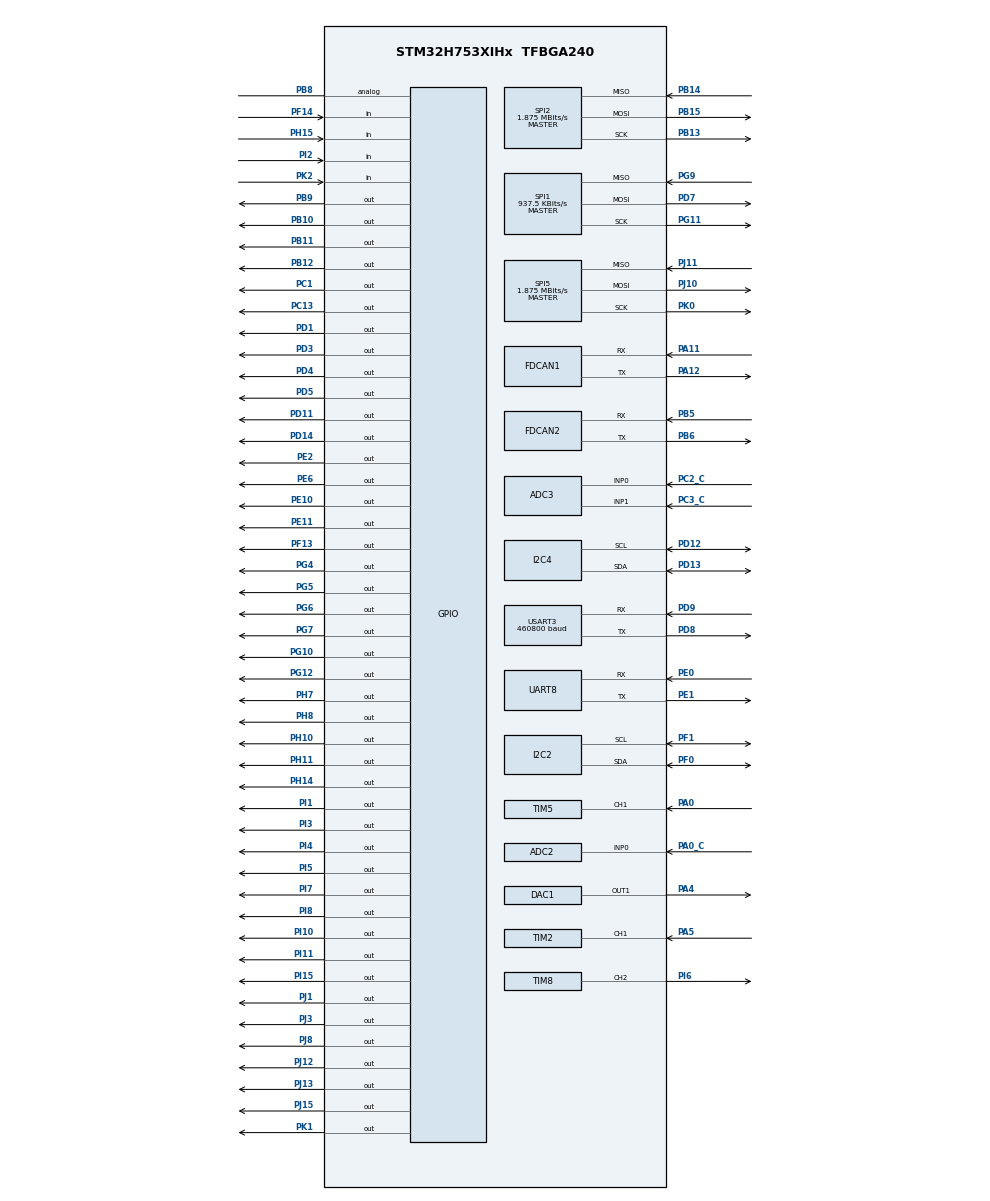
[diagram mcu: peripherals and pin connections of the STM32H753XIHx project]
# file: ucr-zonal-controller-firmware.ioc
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ADC2.Channel-0\#ChannelRegularConversion=ADC_CHANNEL_0
ADC2.ClockPrescaler=ADC_CLOCK_ASYNC_DIV256
ADC2.ContinuousConvMode=ENABLE
ADC2.ConversionDataManagement=ADC_CONVERSIONDATA_DMA_CIRCULAR
ADC2.NbrOfConversionFlag=1
ADC2.OffsetNumber-0\#ChannelRegularConversion=ADC_OFFSET_NONE
ADC2.OffsetSignedSaturation-0\#ChannelRegularConversion=DISABLE
ADC2.Rank-0\#ChannelRegularConversion=1
ADC2.Resolution=ADC_RESOLUTION_12B
ADC2.SamplingTime-0\#ChannelRegularConversion=ADC_SAMPLETIME_810CYCLES_5
ADC3.Channel-2\#ChannelRegularConversion=ADC_CHANNEL_1
ADC3.Channel-3\#ChannelRegularConversion=ADC_CHANNEL_0
ADC3.ClockPrescaler=ADC_CLOCK_ASYNC_DIV256
ADC3.ContinuousConvMode=ENABLE
ADC3.ConversionDataManagement=ADC_CONVERSIONDATA_DMA_CIRCULAR
ADC3.NbrOfConversion=2
ADC3.NbrOfConversionFlag=1
ADC3.OffsetNumber-2\#ChannelRegularConversion=ADC_OFFSET_NONE
ADC3.OffsetNumber-3\#ChannelRegularConversion=ADC_OFFSET_NONE
ADC3.OffsetSignedSaturation-2\#ChannelRegularConversion=DISABLE
ADC3.OffsetSignedSaturation-3\#ChannelRegularConversion=DISABLE
ADC3.Rank-2\#ChannelRegularConversion=1
ADC3.Rank-3\#ChannelRegularConversion=2
ADC3.SamplingTime-2\#ChannelRegularConversion=ADC_SAMPLETIME_810CYCLES_5
ADC3.SamplingTime-3\#ChannelRegularConversion=ADC_SAMPLETIME_810CYCLES_5
CORTEX_M7.default_mode_Activation=1
DAC1.DAC_Channel-DAC_OUT1=DAC_CHANNEL_1
Dma.ADC2.1.Direction=DMA_PERIPH_TO_MEMORY
Dma.ADC2.1.EventEnable=DISABLE
Dma.ADC2.1.FIFOMode=DMA_FIFOMODE_DISABLE
Dma.ADC2.1.Instance=DMA1_Stream1
Dma.ADC2.1.MemDataAlignment=DMA_MDATAALIGN_HALFWORD
Dma.ADC2.1.MemInc=DMA_MINC_ENABLE
Dma.ADC2.1.Mode=DMA_CIRCULAR
Dma.ADC2.1.PeriphDataAlignment=DMA_PDATAALIGN_HALFWORD
Dma.ADC2.1.PeriphInc=DMA_PINC_DISABLE
Dma.ADC2.1.Polarity=HAL_DMAMUX_REQ_GEN_RISING
Dma.ADC2.1.Priority=DMA_PRIORITY_LOW
Dma.ADC2.1.RequestNumber=1
Dma.ADC2.1.SignalID=NONE
Dma.ADC2.1.SyncEnable=DISABLE
Dma.ADC2.1.SyncPolarity=HAL_DMAMUX_SYNC_NO_EVENT
Dma.ADC2.1.SyncRequestNumber=1
Dma.ADC2.1.SyncSignalID=NONE
Dma.ADC3.2.Direction=DMA_PERIPH_TO_MEMORY
Dma.ADC3.2.EventEnable=DISABLE
Dma.ADC3.2.FIFOMode=DMA_FIFOMODE_DISABLE
Dma.ADC3.2.Instance=DMA2_Stream1
Dma.ADC3.2.MemDataAlignment=DMA_MDATAALIGN_HALFWORD
Dma.ADC3.2.MemInc=DMA_MINC_ENABLE
Dma.ADC3.2.Mode=DMA_CIRCULAR
Dma.ADC3.2.PeriphDataAlignment=DMA_PDATAALIGN_HALFWORD
Dma.ADC3.2.PeriphInc=DMA_PINC_DISABLE
Dma.ADC3.2.Polarity=HAL_DMAMUX_REQ_GEN_RISING
Dma.ADC3.2.Priority=DMA_PRIORITY_LOW
Dma.ADC3.2.RequestNumber=1
Dma.ADC3.2.SignalID=NONE
Dma.ADC3.2.SyncEnable=DISABLE
Dma.ADC3.2.SyncPolarity=HAL_DMAMUX_SYNC_NO_EVENT
Dma.ADC3.2.SyncRequestNumber=1
Dma.ADC3.2.SyncSignalID=NONE
Dma.Request0=USART3_RX
Dma.Request1=ADC2
Dma.Request2=ADC3
Dma.USART3_RX.0.Direction=DMA_PERIPH_TO_MEMORY
Dma.USART3_RX.0.EventEnable=DISABLE
Dma.USART3_RX.0.FIFOMode=DMA_FIFOMODE_DISABLE
Dma.USART3_RX.0.Instance=DMA1_Stream0
Dma.USART3_RX.0.MemDataAlignment=DMA_MDATAALIGN_BYTE
Dma.USART3_RX.0.MemInc=DMA_MINC_ENABLE
Dma.USART3_RX.0.Mode=DMA_CIRCULAR
Dma.USART3_RX.0.PeriphDataAlignment=DMA_PDATAALIGN_BYTE
Dma.USART3_RX.0.PeriphInc=DMA_PINC_DISABLE
Dma.USART3_RX.0.Polarity=HAL_DMAMUX_REQ_GEN_RISING
Dma.USART3_RX.0.Priority=DMA_PRIORITY_MEDIUM
Dma.USART3_RX.0.RequestNumber=1
Dma.USART3_RX.0.SignalID=NONE
Dma.USART3_RX.0.SyncEnable=DISABLE
Dma.USART3_RX.0.SyncPolarity=HAL_DMAMUX_SYNC_NO_EVENT
Dma.USART3_RX.0.SyncRequestNumber=1
Dma.USART3_RX.0.SyncSignalID=NONE
FDCAN1.AutoRetransmission=DISABLE
FDCAN1.CalculateBaudRateNominal=499999
FDCAN1.CalculateTimeBitNominal=2000
FDCAN1.CalculateTimeQuantumNominal=250.00000000000003
FDCAN1.DataPrescaler=15
FDCAN1.DataSyncJumpWidth=1
FDCAN1.DataTimeSeg1=2
FDCAN1.DataTimeSeg2=1
FDCAN1.FrameFormat=FDCAN_FRAME_FD_BRS
FDCAN1.Mode=FDCAN_MODE_NORMAL
FDCAN1.NominalPrescaler=30
FDCAN1.NominalSyncJumpWidth=2
FDCAN1.NominalTimeSeg1=5
FDCAN1.NominalTimeSeg2=2
FDCAN1.RxBufferSize=FDCAN_DATA_BYTES_64
FDCAN1.RxFifo0ElmtSize=FDCAN_DATA_BYTES_64
FDCAN1.RxFifo0ElmtsNbr=16
FDCAN1.RxFifo1ElmtSize=FDCAN_DATA_BYTES_64
FDCAN1.RxFifo1ElmtsNbr=16
FDCAN1.StdFiltersNbr=0
FDCAN1.TxElmtSize=FDCAN_DATA_BYTES_64
FDCAN1.TxFifoQueueElmtsNbr=32
FDCAN2.CalculateBaudRateNominal=500000
FDCAN2.CalculateTimeBitNominal=2000
FDCAN2.CalculateTimeQuantumNominal=100.0
FDCAN2.DataPrescaler=12
FDCAN2.DataSyncJumpWidth=8
FDCAN2.DataTimeSeg1=11
FDCAN2.DataTimeSeg2=8
FDCAN2.FrameFormat=FDCAN_FRAME_CLASSIC
FDCAN2.MessageRAMOffset=1280
FDCAN2.Mode=FDCAN_MODE_NORMAL
FDCAN2.NominalPrescaler=12
FDCAN2.NominalSyncJumpWidth=5
FDCAN2.NominalTimeSeg1=14
FDCAN2.NominalTimeSeg2=5
FDCAN2.RxFifo0ElmtSize=FDCAN_DATA_BYTES_8
FDCAN2.RxFifo0ElmtsNbr=16
FDCAN2.RxFifo1ElmtSize=FDCAN_DATA_BYTES_8
FDCAN2.RxFifo1ElmtsNbr=16
FDCAN2.TxElmtSize=FDCAN_DATA_BYTES_8
FDCAN2.TxFifoQueueElmtsNbr=16
FREERTOS.Tasks01=TestTask,41,1024,StartTestTask,Default,NULL,Dynamic,NULL,NULL;SlowTask,8,512,StartSlowTask,Default,NULL,Dynamic,NULL,NULL;MediumTask,16,512,StartMediumTask,Default,NULL,Dynamic,NULL,NULL;FastTask,32,512,StartFastTask,Default,NULL,Dynamic,NULL,NULL;CanClassicTx,24,512,StartCanClassicTx,Default,NULL,Dynamic,NULL,NULL;CanClassicRx,40,512,StartCanClassicRx,Default,NULL,Dynamic,NULL,NULL;ManagerTask,40,512,StartManagerTask,Default,NULL,Dynamic,NULL,NULL;VeryFastTask,16,256,StartVeryFastTask,Default,NULL,Dynamic,NULL,NULL
FREERTOS.configTOTAL_HEAP_SIZE=32768
FREERTOS.configUSE_NEWLIB_REENTRANT=1
I2C2.Timing=0x307075B1
I2C4.Timing=0x307075B1
Mcu.Family=STM32H7
Mcu.Name=STM32H753XIHx
Mcu.Package=TFBGA240
NVIC.ADC3_IRQn=true\:5\:0\:false\:false\:true\:true\:true\:true\:true
NVIC.ADC_IRQn=true\:5\:0\:false\:false\:true\:true\:true\:true\:true
NVIC.DMA1_Stream0_IRQn=true\:5\:0\:false\:false\:true\:true\:false\:true\:true
NVIC.DMA1_Stream1_IRQn=true\:5\:0\:false\:false\:true\:true\:false\:true\:true
NVIC.DMA2_Stream1_IRQn=true\:5\:0\:false\:false\:true\:true\:false\:true\:true
NVIC.FDCAN1_IT0_IRQn=true\:5\:0\:false\:false\:true\:true\:true\:true\:true
NVIC.FDCAN1_IT1_IRQn=true\:5\:0\:false\:false\:true\:true\:true\:true\:true
NVIC.FDCAN2_IT0_IRQn=true\:5\:0\:false\:false\:true\:true\:true\:true\:true
NVIC.FDCAN2_IT1_IRQn=true\:5\:0\:false\:false\:true\:true\:true\:true\:true
NVIC.PriorityGroup=NVIC_PRIORITYGROUP_4
NVIC.SPI1_IRQn=true\:5\:0\:false\:false\:true\:true\:true\:true\:true
NVIC.TIM1_UP_IRQn=true\:15\:0\:false\:false\:true\:false\:false\:true\:true
NVIC.TIM2_IRQn=true\:5\:0\:false\:false\:true\:true\:true\:true\:true
NVIC.TIM5_IRQn=true\:5\:0\:false\:false\:true\:true\:true\:true\:true
NVIC.TimeBase=TIM1_UP_IRQn
NVIC.TimeBaseIP=TIM1
NVIC.USART3_IRQn=true\:5\:0\:false\:false\:true\:true\:true\:true\:true
PA0.Signal=S_TIM5_CH1
PA0_C.Signal=ADCx_INP0
PA11.Mode=FDCAN_Activate
PA11.Signal=FDCAN1_RX
PA12.Mode=FDCAN_Activate
PA12.Signal=FDCAN1_TX
PA13\ (JTMS/SWDIO).Mode=JTAG_4_pins
PA13\ (JTMS/SWDIO).Signal=DEBUG_JTMS-SWDIO
PA14\ (JTCK/SWCLK).Mode=JTAG_4_pins
PA14\ (JTCK/SWCLK).Signal=DEBUG_JTCK-SWCLK
PA15\ (JTDI).Mode=JTAG_4_pins
PA15\ (JTDI).Signal=DEBUG_JTDI
PA4.Signal=COMP_DAC11_group
PA5.Signal=S_TIM2_CH1_ETR
PB10.Signal=GPIO_Output
PB11.Signal=GPIO_Output
PB12.Signal=GPIO_Output
PB13.Mode=Full_Duplex_Master
PB13.Signal=SPI2_SCK
PB14.Mode=Full_Duplex_Master
PB14.Signal=SPI2_MISO
PB15.Mode=Full_Duplex_Master
PB15.Signal=SPI2_MOSI
PB3\ (JTDO/TRACESWO).Mode=JTAG_4_pins
PB3\ (JTDO/TRACESWO).Signal=DEBUG_JTDO-SWO
PB5.Mode=FDCAN_Activate
PB5.Signal=FDCAN2_RX
PB6.Mode=FDCAN_Activate
PB6.Signal=FDCAN2_TX
PB8.Signal=GPIO_Analog
PB9.Signal=GPIO_Output
PC1.Signal=GPIO_Output
PC13.Signal=GPIO_Output
PC14-OSC32_IN\ (OSC32_IN).Mode=LSE-External-Oscillator
PC14-OSC32_IN\ (OSC32_IN).Signal=RCC_OSC32_IN
PC15-OSC32_OUT\ (OSC32_OUT).Mode=LSE-External-Oscillator
PC15-OSC32_OUT\ (OSC32_OUT).Signal=RCC_OSC32_OUT
PC2_C.Mode=IN0-Single-Ended
PC2_C.Signal=ADC3_INP0
PC3_C.Mode=IN1-Single-Ended
PC3_C.Signal=ADC3_INP1
PD1.Signal=GPIO_Output
PD11.Signal=GPIO_Output
PD12.Mode=I2C
PD12.Signal=I2C4_SCL
PD13.Mode=I2C
PD13.Signal=I2C4_SDA
PD14.Signal=GPIO_Output
PD3.Signal=GPIO_Output
PD4.Signal=GPIO_Output
PD5.Signal=GPIO_Output
PD7.Mode=Full_Duplex_Master
PD7.Signal=SPI1_MOSI
PD8.Mode=Asynchronous
PD8.Signal=USART3_TX
PD9.Mode=Asynchronous
PD9.Signal=USART3_RX
PE0.Mode=Asynchronous
PE0.Signal=UART8_RX
PE1.Mode=Asynchronous
PE1.Signal=UART8_TX
PE10.Signal=GPIO_Output
PE11.Signal=GPIO_Output
PE2.Signal=GPIO_Output
PE6.Signal=GPIO_Output
PF0.Mode=I2C
PF0.Signal=I2C2_SDA
PF1.Mode=I2C
PF1.Signal=I2C2_SCL
PF13.PinState=GPIO_PIN_SET
PF13.Signal=GPIO_Output
PF14.GPIO_PuPd=GPIO_PULLUP
PF14.Signal=GPIO_Input
PG10.Signal=GPIO_Output
PG11.Mode=Full_Duplex_Master
PG11.Signal=SPI1_SCK
PG12.Signal=GPIO_Output
PG4.Signal=GPIO_Output
PG5.Signal=GPIO_Output
PG6.Signal=GPIO_Output
PG7.Signal=GPIO_Output
PG9.Mode=Full_Duplex_Master
PG9.Signal=SPI1_MISO
PH0-OSC_IN\ (PH0).Mode=HSE-External-Oscillator
PH0-OSC_IN\ (PH0).Signal=RCC_OSC_IN
PH1-OSC_OUT\ (PH1).Mode=HSE-External-Oscillator
PH1-OSC_OUT\ (PH1).Signal=RCC_OSC_OUT
PH10.Signal=GPIO_Output
PH11.Signal=GPIO_Output
PH14.Signal=GPIO_Output
PH15.Signal=GPIO_Input
PH7.Signal=GPIO_Output
PH8.Signal=GPIO_Output
PI1.Signal=GPIO_Output
PI10.Signal=GPIO_Output
PI11.Signal=GPIO_Output
PI15.Signal=GPIO_Output
PI2.Signal=GPIO_Input
PI3.Signal=GPIO_Output
PI4.Signal=GPIO_Output
PI5.Signal=GPIO_Output
PI6.Signal=S_TIM8_CH2
PI7.Signal=GPIO_Output
PI8.Signal=GPIO_Output
PJ1.Signal=GPIO_Output
PJ10.Mode=Full_Duplex_Master
PJ10.Signal=SPI5_MOSI
PJ11.Mode=Full_Duplex_Master
PJ11.Signal=SPI5_MISO
PJ12.Signal=GPIO_Output
PJ13.PinState=GPIO_PIN_SET
PJ13.Signal=GPIO_Output
PJ15.Signal=GPIO_Output
PJ3.PinState=GPIO_PIN_SET
PJ3.Signal=GPIO_Output
PJ8.Signal=GPIO_Output
PK0.Mode=Full_Duplex_Master
PK0.Signal=SPI5_SCK
PK1.Signal=GPIO_Output
PK2.Signal=GPIO_Input
ProjectManager.HeapSize=0x200
ProjectManager.StackSize=0x400
ProjectManager.TargetToolchain=STM32CubeIDE
RCC.ADCFreq_Value=80000000
RCC.APB1Freq_Value=120000000
RCC.APB2Freq_Value=120000000
RCC.APB3Freq_Value=120000000
RCC.APB4Freq_Value=120000000
RCC.CortexFreq_Value=480000000
RCC.D1PPRE=RCC_APB3_DIV2
RCC.D2PPRE1=RCC_APB1_DIV2
RCC.D2PPRE2=RCC_APB2_DIV2
RCC.D3PPRE=RCC_APB4_DIV2
RCC.DIVM1=5
RCC.DIVM2=5
RCC.DIVN1=192
RCC.DIVN2=32
RCC.DIVQ1=8
RCC.HCLKFreq_Value=240000000
RCC.HPRE=RCC_HCLK_DIV2
RCC.HSE_Timout=500
RCC.HSE_VALUE=25000000
RCC.PLL2FRACN=0
RCC.PLL3FRACN=0
RCC.PLLFRACN=0
RCC.PLLSourceVirtual=RCC_PLLSOURCE_HSE
RCC.RTCClockSelection=RCC_RTCCLKSOURCE_LSE
RCC.SYSCLKFreq_VALUE=480000000
RCC.SYSCLKSource=RCC_SYSCLKSOURCE_PLLCLK
RCC.USBFreq_Value=120000000
SH.ADCx_INP0.0=ADC2_INP0,IN0-Single-Ended
SH.COMP_DAC11_group.0=DAC1_OUT1,DAC_OUT1
SH.S_TIM2_CH1_ETR.0=TIM2_CH1,Input_Capture1_from_TI1
SH.S_TIM5_CH1.0=TIM5_CH1,Input_Capture1_from_TI1
SH.S_TIM8_CH2.0=TIM8_CH2,PWM Generation2 CH2
SPI1.BaudRatePrescaler=SPI_BAUDRATEPRESCALER_128
SPI1.CLKPhase=SPI_PHASE_2EDGE
SPI1.CalculateBaudRate=937.5 KBits/s
SPI1.DataSize=SPI_DATASIZE_8BIT
SPI1.Direction=SPI_DIRECTION_2LINES
SPI1.Mode=SPI_MODE_MASTER
SPI1.VirtualType=VM_MASTER
SPI2.BaudRatePrescaler=SPI_BAUDRATEPRESCALER_64
SPI2.CalculateBaudRate=1.875 MBits/s
SPI2.DataSize=SPI_DATASIZE_8BIT
SPI2.Direction=SPI_DIRECTION_2LINES
SPI2.Mode=SPI_MODE_MASTER
SPI2.VirtualType=VM_MASTER
SPI5.BaudRatePrescaler=SPI_BAUDRATEPRESCALER_64
SPI5.CLKPhase=SPI_PHASE_1EDGE
SPI5.CalculateBaudRate=1.875 MBits/s
SPI5.DataSize=SPI_DATASIZE_8BIT
SPI5.Direction=SPI_DIRECTION_2LINES
SPI5.Mode=SPI_MODE_MASTER
SPI5.VirtualType=VM_MASTER
TIM2.Channel-Input_Capture1_from_TI1=TIM_CHANNEL_1
TIM2.Period=4294967295
TIM2.Prescaler=239
TIM5.Channel-Input_Capture1_from_TI1=TIM_CHANNEL_1
TIM5.Prescaler=239
TIM8.AutoReloadPreload=TIM_AUTORELOAD_PRELOAD_ENABLE
TIM8.Channel-PWM\ Generation2\ CH2=TIM_CHANNEL_2
TIM8.Prescaler=35
USART3.BaudRate=460800
USART3.VirtualMode-Asynchronous=VM_ASYNC
VP_FREERTOS_VS_CMSIS_V2.Mode=CMSIS_V2
VP_MEMORYMAP_VS_MEMORYMAP.Mode=CurAppReg
VP_RTC_VS_RTC_Activate.Mode=RTC_Enabled
VP_SYS_VS_tim1.Mode=TIM1
VP_TIM2_VS_ClockSourceINT.Mode=Internal
VP_TIM3_VS_ClockSourceINT.Mode=Internal
VP_TIM5_VS_ClockSourceINT.Mode=Internal
VP_VREFBUF_V_VREFBUF.Mode=ExternalMode
board=custom

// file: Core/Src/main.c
/* USER CODE BEGIN Header */
/**
  ******************************************************************************
  * @file           : main.c
  * @brief          : Main program body
  ******************************************************************************
  * @attention
  *
  * Copyright (c) 2026 STMicroelectronics.
  * All rights reserved.
  *
  * This software is licensed under terms that can be found in the LICENSE file
  * in the root directory of this software component.
  * If no LICENSE file comes with this software, it is provided AS-IS.
  *
  ******************************************************************************
  */
/* USER CODE END Header */
#include "main.h"
#include "cmsis_os.h"

/* USER CODE BEGIN Includes */

#include "task_test.h"
#include "task_fast.h"
#include "task_very_fast.h"
#include "task_medium.h"
#include "task_slow.h"
#include "task_can_classic_tx.h"
#include "task_can_classic_rx.h"
#include "task_manager.h"

/* USER CODE END Includes */

ADC_HandleTypeDef hadc2;
ADC_HandleTypeDef hadc3;
DMA_HandleTypeDef hdma_adc2;
DMA_HandleTypeDef hdma_adc3;

DAC_HandleTypeDef hdac1;

FDCAN_HandleTypeDef hfdcan1;
FDCAN_HandleTypeDef hfdcan2;

I2C_HandleTypeDef hi2c2;
I2C_HandleTypeDef hi2c4;

RTC_HandleTypeDef hrtc;

SPI_HandleTypeDef hspi1;
SPI_HandleTypeDef hspi2;
SPI_HandleTypeDef hspi5;

TIM_HandleTypeDef htim2;
TIM_HandleTypeDef htim3;
TIM_HandleTypeDef htim5;
TIM_HandleTypeDef htim8;

UART_HandleTypeDef huart8;
UART_HandleTypeDef huart3;
DMA_HandleTypeDef hdma_usart3_rx;

/* Definitions for TestTask */
osThreadId_t TestTaskHandle;
const osThreadAttr_t TestTask_attributes = {
  .name = "TestTask",
  .stack_size = 1024 * 4,
  .priority = (osPriority_t) osPriorityHigh1,
};
/* Definitions for SlowTask */
osThreadId_t SlowTaskHandle;
const osThreadAttr_t SlowTask_attributes = {
  .name = "SlowTask",
  .stack_size = 512 * 4,
  .priority = (osPriority_t) osPriorityLow,
};
/* Definitions for MediumTask */
osThreadId_t MediumTaskHandle;
const osThreadAttr_t MediumTask_attributes = {
  .name = "MediumTask",
  .stack_size = 512 * 4,
  .priority = (osPriority_t) osPriorityBelowNormal,
};
/* Definitions for FastTask */
osThreadId_t FastTaskHandle;
const osThreadAttr_t FastTask_attributes = {
  .name = "FastTask",
  .stack_size = 512 * 4,
  .priority = (osPriority_t) osPriorityAboveNormal,
};
/* Definitions for CanClassicTx */
osThreadId_t CanClassicTxHandle;
const osThreadAttr_t CanClassicTx_attributes = {
  .name = "CanClassicTx",
  .stack_size = 512 * 4,
  .priority = (osPriority_t) osPriorityNormal,
};
/* Definitions for CanClassicRx */
osThreadId_t CanClassicRxHandle;
const osThreadAttr_t CanClassicRx_attributes = {
  .name = "CanClassicRx",
  .stack_size = 512 * 4,
  .priority = (osPriority_t) osPriorityHigh,
};
/* Definitions for ManagerTask */
osThreadId_t ManagerTaskHandle;
const osThreadAttr_t ManagerTask_attributes = {
  .name = "ManagerTask",
  .stack_size = 512 * 4,
  .priority = (osPriority_t) osPriorityHigh,
};
/* Definitions for VeryFastTask */
osThreadId_t VeryFastTaskHandle;
const osThreadAttr_t VeryFastTask_attributes = {
  .name = "VeryFastTask",
  .stack_size = 256 * 4,
  .priority = (osPriority_t) osPriorityBelowNormal,
};
/* USER CODE BEGIN PV */
/* Definitions for Can1TxQueue */

uint32_t captureValue = 0;
uint32_t previousCaptureValue = 0;
uint32_t frequency = 0;

osMessageQueueId_t Can1TxQueueHandle;
const osMessageQueueAttr_t Can1TxQueue_attributes = {
  .name = "Can1TxQueue"
};

osMessageQueueId_t Can1RxQueueHandle;
const osMessageQueueAttr_t Can1RxQueue_attributes = {
  .name = "Can1RxQueue"
};

osMessageQueueId_t Can2TxQueueHandle;
const osMessageQueueAttr_t Can2TxQueue_attributes = {
  .name = "Can2TxQueue"
};

osMessageQueueId_t Can2RxQueueHandle;
const osMessageQueueAttr_t Can2RxQueue_attributes = {
  .name = "Can2RxQueue"
};
/* USER CODE END PV */

void SystemClock_Config(void);
void PeriphCommonClock_Config(void);
static void MPU_Config(void);
static void MX_GPIO_Init(void);
static void MX_DMA_Init(void);
static void MX_ADC3_Init(void);
static void MX_DAC1_Init(void);
static void MX_FDCAN1_Init(void);
static void MX_FDCAN2_Init(void);
static void MX_I2C2_Init(void);
static void MX_I2C4_Init(void);
static void MX_SPI1_Init(void);
static void MX_SPI2_Init(void);
static void MX_SPI5_Init(void);
static void MX_UART8_Init(void);
static void MX_USART3_UART_Init(void);
static void MX_TIM3_Init(void);
static void MX_TIM2_Init(void);
static void MX_RTC_Init(void);
static void MX_ADC2_Init(void);
static void MX_TIM8_Init(void);
static void MX_TIM5_Init(void);
void StartTestTask(void *argument);
void StartSlowTask(void *argument);
void StartMediumTask(void *argument);
void StartFastTask(void *argument);
void StartCanClassicTx(void *argument);
void StartCanClassicRx(void *argument);
void StartManagerTask(void *argument);
void StartVeryFastTask(void *argument);

/* USER CODE BEGIN 0 */

//void HAL_TIM_IC_CaptureCallback(TIM_HandleTypeDef *htim)
//{
//    if (htim->Channel == HAL_TIM_ACTIVE_CHANNEL_1) {
//        captureValue = HAL_TIM_ReadCapturedValue(htim, TIM_CHANNEL_1);
//        frequency = HAL_RCC_GetPCLK1Freq() / (captureValue - previousCaptureValue);
//        previousCaptureValue = captureValue;
//    }
//}

/* USER CODE END 0 */

int main(void)
{

  /* MPU Configuration--------------------------------------------------------*/
  MPU_Config();

  /* MCU Configuration--------------------------------------------------------*/

  /* Reset of all peripherals, Initializes the Flash interface and the Systick. */
  HAL_Init();

  /* Configure the system clock */
  SystemClock_Config();

  /* Configure the peripherals common clocks */
  PeriphCommonClock_Config();

  /* Initialize all configured peripherals */
  MX_GPIO_Init();
  MX_DMA_Init();
  MX_ADC3_Init();
  MX_DAC1_Init();
  MX_FDCAN1_Init();
  MX_FDCAN2_Init();
  MX_I2C2_Init();
  MX_I2C4_Init();
  MX_SPI1_Init();
  MX_SPI2_Init();
  MX_SPI5_Init();
  MX_UART8_Init();
  MX_USART3_UART_Init();
  MX_TIM3_Init();
  MX_TIM2_Init();
  MX_RTC_Init();
  MX_ADC2_Init();
  MX_TIM8_Init();
  MX_TIM5_Init();

  /* Init scheduler */
  osKernelInitialize();

  /* USER CODE BEGIN RTOS_QUEUES */
  Can1TxQueueHandle = osMessageQueueNew (16, sizeof(can_msg_t), &Can1TxQueue_attributes);
  Can1RxQueueHandle = osMessageQueueNew (16, sizeof(can_msg_t), &Can1RxQueue_attributes);

  Can2TxQueueHandle = osMessageQueueNew (16, sizeof(can_msg_t), &Can2TxQueue_attributes);
  Can2RxQueueHandle = osMessageQueueNew (16, sizeof(can_msg_t), &Can2RxQueue_attributes);
  /* USER CODE END RTOS_QUEUES */

  /* Create the thread(s) */
  /* creation of TestTask */
  TestTaskHandle = osThreadNew(StartTestTask, NULL, &TestTask_attributes);

  /* creation of SlowTask */
  SlowTaskHandle = osThreadNew(StartSlowTask, NULL, &SlowTask_attributes);

  /* creation of MediumTask */
  MediumTaskHandle = osThreadNew(StartMediumTask, NULL, &MediumTask_attributes);

  /* creation of FastTask */
  FastTaskHandle = osThreadNew(StartFastTask, NULL, &FastTask_attributes);

  /* creation of CanClassicTx */
  CanClassicTxHandle = osThreadNew(StartCanClassicTx, NULL, &CanClassicTx_attributes);

  /* creation of CanClassicRx */
  CanClassicRxHandle = osThreadNew(StartCanClassicRx, NULL, &CanClassicRx_attributes);

  /* creation of ManagerTask */
  ManagerTaskHandle = osThreadNew(StartManagerTask, NULL, &ManagerTask_attributes);

  /* creation of VeryFastTask */
  VeryFastTaskHandle = osThreadNew(StartVeryFastTask, NULL, &VeryFastTask_attributes);

  /* Start scheduler */
  osKernelStart();

  /* We should never get here as control is now taken by the scheduler */

  /* Infinite loop */
  while (1)
  {

  }
}

void SystemClock_Config(void)
{
  RCC_OscInitTypeDef RCC_OscInitStruct = {0};
  RCC_ClkInitTypeDef RCC_ClkInitStruct = {0};

  /** Supply configuration update enable
  */
  HAL_PWREx_ConfigSupply(PWR_LDO_SUPPLY);

  /** Configure the main internal regulator output voltage
  */
  __HAL_PWR_VOLTAGESCALING_CONFIG(PWR_REGULATOR_VOLTAGE_SCALE0);

  while(!__HAL_PWR_GET_FLAG(PWR_FLAG_VOSRDY)) {}

  /** Configure LSE Drive Capability
  */
  HAL_PWR_EnableBkUpAccess();
  __HAL_RCC_LSEDRIVE_CONFIG(RCC_LSEDRIVE_LOW);

  /** Initializes the RCC Oscillators according to the specified parameters
  * in the RCC_OscInitTypeDef structure.
  */
  RCC_OscInitStruct.OscillatorType = RCC_OSCILLATORTYPE_HSE|RCC_OSCILLATORTYPE_LSE;
  RCC_OscInitStruct.HSEState = RCC_HSE_ON;
  RCC_OscInitStruct.LSEState = RCC_LSE_ON;
  RCC_OscInitStruct.PLL.PLLState = RCC_PLL_ON;
  RCC_OscInitStruct.PLL.PLLSource = RCC_PLLSOURCE_HSE;
  RCC_OscInitStruct.PLL.PLLM = 5;
  RCC_OscInitStruct.PLL.PLLN = 192;
  RCC_OscInitStruct.PLL.PLLP = 2;
  RCC_OscInitStruct.PLL.PLLQ = 8;
  RCC_OscInitStruct.PLL.PLLR = 2;
  RCC_OscInitStruct.PLL.PLLRGE = RCC_PLL1VCIRANGE_2;
  RCC_OscInitStruct.PLL.PLLVCOSEL = RCC_PLL1VCOWIDE;
  RCC_OscInitStruct.PLL.PLLFRACN = 0;
  if (HAL_RCC_OscConfig(&RCC_OscInitStruct) != HAL_OK)
  {
    Error_Handler();
  }

  /** Initializes the CPU, AHB and APB buses clocks
  */
  RCC_ClkInitStruct.ClockType = RCC_CLOCKTYPE_HCLK|RCC_CLOCKTYPE_SYSCLK
                              |RCC_CLOCKTYPE_PCLK1|RCC_CLOCKTYPE_PCLK2
                              |RCC_CLOCKTYPE_D3PCLK1|RCC_CLOCKTYPE_D1PCLK1;
  RCC_ClkInitStruct.SYSCLKSource = RCC_SYSCLKSOURCE_PLLCLK;
  RCC_ClkInitStruct.SYSCLKDivider = RCC_SYSCLK_DIV1;
  RCC_ClkInitStruct.AHBCLKDivider = RCC_HCLK_DIV2;
  RCC_ClkInitStruct.APB3CLKDivider = RCC_APB3_DIV2;
  RCC_ClkInitStruct.APB1CLKDivider = RCC_APB1_DIV2;
  RCC_ClkInitStruct.APB2CLKDivider = RCC_APB2_DIV2;
  RCC_ClkInitStruct.APB4CLKDivider = RCC_APB4_DIV2;

  if (HAL_RCC_ClockConfig(&RCC_ClkInitStruct, FLASH_LATENCY_4) != HAL_OK)
  {
    Error_Handler();
  }
}

void PeriphCommonClock_Config(void)
{
  RCC_PeriphCLKInitTypeDef PeriphClkInitStruct = {0};

  /** Initializes the peripherals clock
  */
  PeriphClkInitStruct.PeriphClockSelection = RCC_PERIPHCLK_ADC;
  PeriphClkInitStruct.PLL2.PLL2M = 5;
  PeriphClkInitStruct.PLL2.PLL2N = 32;
  PeriphClkInitStruct.PLL2.PLL2P = 2;
  PeriphClkInitStruct.PLL2.PLL2Q = 2;
  PeriphClkInitStruct.PLL2.PLL2R = 2;
  PeriphClkInitStruct.PLL2.PLL2RGE = RCC_PLL2VCIRANGE_2;
  PeriphClkInitStruct.PLL2.PLL2VCOSEL = RCC_PLL2VCOMEDIUM;
  PeriphClkInitStruct.PLL2.PLL2FRACN = 0;
  PeriphClkInitStruct.AdcClockSelection = RCC_ADCCLKSOURCE_PLL2;
  if (HAL_RCCEx_PeriphCLKConfig(&PeriphClkInitStruct) != HAL_OK)
  {
    Error_Handler();
  }
}

static void MX_ADC2_Init(void)
{

  ADC_ChannelConfTypeDef sConfig = {0};

  /** Common config
  */
  hadc2.Instance = ADC2;
  hadc2.Init.ClockPrescaler = ADC_CLOCK_ASYNC_DIV256;
  hadc2.Init.Resolution = ADC_RESOLUTION_12B;
  hadc2.Init.ScanConvMode = ADC_SCAN_DISABLE;
  hadc2.Init.EOCSelection = ADC_EOC_SINGLE_CONV;
  hadc2.Init.LowPowerAutoWait = DISABLE;
  hadc2.Init.ContinuousConvMode = ENABLE;
  hadc2.Init.NbrOfConversion = 1;
  hadc2.Init.DiscontinuousConvMode = DISABLE;
  hadc2.Init.ExternalTrigConv = ADC_SOFTWARE_START;
  hadc2.Init.ExternalTrigConvEdge = ADC_EXTERNALTRIGCONVEDGE_NONE;
  hadc2.Init.ConversionDataManagement = ADC_CONVERSIONDATA_DMA_CIRCULAR;
  hadc2.Init.Overrun = ADC_OVR_DATA_PRESERVED;
  hadc2.Init.LeftBitShift = ADC_LEFTBITSHIFT_NONE;
  hadc2.Init.OversamplingMode = DISABLE;
  hadc2.Init.Oversampling.Ratio = 1;
  if (HAL_ADC_Init(&hadc2) != HAL_OK)
  {
    Error_Handler();
  }

  /** Configure Regular Channel
  */
  sConfig.Channel = ADC_CHANNEL_0;
  sConfig.Rank = ADC_REGULAR_RANK_1;
  sConfig.SamplingTime = ADC_SAMPLETIME_810CYCLES_5;
  sConfig.SingleDiff = ADC_SINGLE_ENDED;
  sConfig.OffsetNumber = ADC_OFFSET_NONE;
  sConfig.Offset = 0;
  sConfig.OffsetSignedSaturation = DISABLE;
  if (HAL_ADC_ConfigChannel(&hadc2, &sConfig) != HAL_OK)
  {
    Error_Handler();
  }

}

static void MX_ADC3_Init(void)
{

  ADC_ChannelConfTypeDef sConfig = {0};

  /** Common config
  */
  hadc3.Instance = ADC3;
  hadc3.Init.ClockPrescaler = ADC_CLOCK_ASYNC_DIV256;
  hadc3.Init.Resolution = ADC_RESOLUTION_16B;
  hadc3.Init.ScanConvMode = ADC_SCAN_ENABLE;
  hadc3.Init.EOCSelection = ADC_EOC_SINGLE_CONV;
  hadc3.Init.LowPowerAutoWait = DISABLE;
  hadc3.Init.ContinuousConvMode = ENABLE;
  hadc3.Init.NbrOfConversion = 2;
  hadc3.Init.DiscontinuousConvMode = DISABLE;
  hadc3.Init.ExternalTrigConv = ADC_SOFTWARE_START;
  hadc3.Init.ExternalTrigConvEdge = ADC_EXTERNALTRIGCONVEDGE_NONE;
  hadc3.Init.ConversionDataManagement = ADC_CONVERSIONDATA_DMA_CIRCULAR;
  hadc3.Init.Overrun = ADC_OVR_DATA_PRESERVED;
  hadc3.Init.LeftBitShift = ADC_LEFTBITSHIFT_NONE;
  hadc3.Init.OversamplingMode = DISABLE;
  hadc3.Init.Oversampling.Ratio = 1;
  if (HAL_ADC_Init(&hadc3) != HAL_OK)
  {
    Error_Handler();
  }

  /** Configure Regular Channel
  */
  sConfig.Channel = ADC_CHANNEL_1;
  sConfig.Rank = ADC_REGULAR_RANK_1;
  sConfig.SamplingTime = ADC_SAMPLETIME_810CYCLES_5;
  sConfig.SingleDiff = ADC_SINGLE_ENDED;
  sConfig.OffsetNumber = ADC_OFFSET_NONE;
  sConfig.Offset = 0;
  sConfig.OffsetSignedSaturation = DISABLE;
  if (HAL_ADC_ConfigChannel(&hadc3, &sConfig) != HAL_OK)
  {
    Error_Handler();
  }

  /** Configure Regular Channel
  */
  sConfig.Channel = ADC_CHANNEL_0;
  sConfig.Rank = ADC_REGULAR_RANK_2;
  if (HAL_ADC_ConfigChannel(&hadc3, &sConfig) != HAL_OK)
  {
    Error_Handler();
  }

}

static void MX_DAC1_Init(void)
{

  DAC_ChannelConfTypeDef sConfig = {0};

  /** DAC Initialization
  */
  hdac1.Instance = DAC1;
  if (HAL_DAC_Init(&hdac1) != HAL_OK)
  {
    Error_Handler();
  }

  /** DAC channel OUT1 config
  */
  sConfig.DAC_SampleAndHold = DAC_SAMPLEANDHOLD_DISABLE;
  sConfig.DAC_Trigger = DAC_TRIGGER_NONE;
  sConfig.DAC_OutputBuffer = DAC_OUTPUTBUFFER_ENABLE;
  sConfig.DAC_ConnectOnChipPeripheral = DAC_CHIPCONNECT_DISABLE;
  sConfig.DAC_UserTrimming = DAC_TRIMMING_FACTORY;
  if (HAL_DAC_ConfigChannel(&hdac1, &sConfig, DAC_CHANNEL_1) != HAL_OK)
  {
    Error_Handler();
  }

}

static void MX_FDCAN1_Init(void)
{

  hfdcan1.Instance = FDCAN1;
  hfdcan1.Init.FrameFormat = FDCAN_FRAME_FD_BRS;
  hfdcan1.Init.Mode = FDCAN_MODE_NORMAL;
  hfdcan1.Init.AutoRetransmission = DISABLE;
  hfdcan1.Init.TransmitPause = DISABLE;
  hfdcan1.Init.ProtocolException = DISABLE;
  hfdcan1.Init.NominalPrescaler = 30;
  hfdcan1.Init.NominalSyncJumpWidth = 2;
  hfdcan1.Init.NominalTimeSeg1 = 5;
  hfdcan1.Init.NominalTimeSeg2 = 2;
  hfdcan1.Init.DataPrescaler = 15;
  hfdcan1.Init.DataSyncJumpWidth = 1;
  hfdcan1.Init.DataTimeSeg1 = 2;
  hfdcan1.Init.DataTimeSeg2 = 1;
  hfdcan1.Init.MessageRAMOffset = 0;
  hfdcan1.Init.StdFiltersNbr = 0;
  hfdcan1.Init.ExtFiltersNbr = 0;
  hfdcan1.Init.RxFifo0ElmtsNbr = 16;
  hfdcan1.Init.RxFifo0ElmtSize = FDCAN_DATA_BYTES_64;
  hfdcan1.Init.RxFifo1ElmtsNbr = 16;
  hfdcan1.Init.RxFifo1ElmtSize = FDCAN_DATA_BYTES_64;
  hfdcan1.Init.RxBuffersNbr = 0;
  hfdcan1.Init.RxBufferSize = FDCAN_DATA_BYTES_64;
  hfdcan1.Init.TxEventsNbr = 0;
  hfdcan1.Init.TxBuffersNbr = 0;
  hfdcan1.Init.TxFifoQueueElmtsNbr = 32;
  hfdcan1.Init.TxFifoQueueMode = FDCAN_TX_FIFO_OPERATION;
  hfdcan1.Init.TxElmtSize = FDCAN_DATA_BYTES_64;
  if (HAL_FDCAN_Init(&hfdcan1) != HAL_OK)
  {
    Error_Handler();
  }
  /* USER CODE BEGIN FDCAN1_Init 2 */
  //HAL_FDCAN_ConfigTxDelayCompensation(&hfdcan1, 40, 0);   // offset = (1 + DataSeg1) * prescaler = 20, filter = 0
  //HAL_FDCAN_EnableTxDelayCompensation(&hfdcan1);
  /* USER CODE END FDCAN1_Init 2 */

}

static void MX_FDCAN2_Init(void)
{

  hfdcan2.Instance = FDCAN2;
  hfdcan2.Init.FrameFormat = FDCAN_FRAME_CLASSIC;
  hfdcan2.Init.Mode = FDCAN_MODE_NORMAL;
  hfdcan2.Init.AutoRetransmission = DISABLE;
  hfdcan2.Init.TransmitPause = DISABLE;
  hfdcan2.Init.ProtocolException = DISABLE;
  hfdcan2.Init.NominalPrescaler = 12;
  hfdcan2.Init.NominalSyncJumpWidth = 5;
  hfdcan2.Init.NominalTimeSeg1 = 14;
  hfdcan2.Init.NominalTimeSeg2 = 5;
  hfdcan2.Init.DataPrescaler = 12;
  hfdcan2.Init.DataSyncJumpWidth = 8;
  hfdcan2.Init.DataTimeSeg1 = 11;
  hfdcan2.Init.DataTimeSeg2 = 8;
  hfdcan2.Init.MessageRAMOffset = 1280;
  hfdcan2.Init.StdFiltersNbr = 0;
  hfdcan2.Init.ExtFiltersNbr = 0;
  hfdcan2.Init.RxFifo0ElmtsNbr = 16;
  hfdcan2.Init.RxFifo0ElmtSize = FDCAN_DATA_BYTES_8;
  hfdcan2.Init.RxFifo1ElmtsNbr = 16;
  hfdcan2.Init.RxFifo1ElmtSize = FDCAN_DATA_BYTES_8;
  hfdcan2.Init.RxBuffersNbr = 0;
  hfdcan2.Init.RxBufferSize = FDCAN_DATA_BYTES_8;
  hfdcan2.Init.TxEventsNbr = 0;
  hfdcan2.Init.TxBuffersNbr = 0;
  hfdcan2.Init.TxFifoQueueElmtsNbr = 16;
  hfdcan2.Init.TxFifoQueueMode = FDCAN_TX_FIFO_OPERATION;
  hfdcan2.Init.TxElmtSize = FDCAN_DATA_BYTES_8;
  if (HAL_FDCAN_Init(&hfdcan2) != HAL_OK)
  {
    Error_Handler();
  }

}

static void MX_I2C2_Init(void)
{

  hi2c2.Instance = I2C2;
  hi2c2.Init.Timing = 0x307075B1;
  hi2c2.Init.OwnAddress1 = 0;
  hi2c2.Init.AddressingMode = I2C_ADDRESSINGMODE_7BIT;
  hi2c2.Init.DualAddressMode = I2C_DUALADDRESS_DISABLE;
  hi2c2.Init.OwnAddress2 = 0;
  hi2c2.Init.OwnAddress2Masks = I2C_OA2_NOMASK;
  hi2c2.Init.GeneralCallMode = I2C_GENERALCALL_DISABLE;
  hi2c2.Init.NoStretchMode = I2C_NOSTRETCH_DISABLE;
  if (HAL_I2C_Init(&hi2c2) != HAL_OK)
  {
    Error_Handler();
  }

  /** Configure Analogue filter
  */
  if (HAL_I2CEx_ConfigAnalogFilter(&hi2c2, I2C_ANALOGFILTER_ENABLE) != HAL_OK)
  {
    Error_Handler();
  }

  /** Configure Digital filter
  */
  if (HAL_I2CEx_ConfigDigitalFilter(&hi2c2, 0) != HAL_OK)
  {
    Error_Handler();
  }

}

static void MX_I2C4_Init(void)
{

  hi2c4.Instance = I2C4;
  hi2c4.Init.Timing = 0x307075B1;
  hi2c4.Init.OwnAddress1 = 0;
  hi2c4.Init.AddressingMode = I2C_ADDRESSINGMODE_7BIT;
  hi2c4.Init.DualAddressMode = I2C_DUALADDRESS_DISABLE;
  hi2c4.Init.OwnAddress2 = 0;
  hi2c4.Init.OwnAddress2Masks = I2C_OA2_NOMASK;
  hi2c4.Init.GeneralCallMode = I2C_GENERALCALL_DISABLE;
  hi2c4.Init.NoStretchMode = I2C_NOSTRETCH_DISABLE;
  if (HAL_I2C_Init(&hi2c4) != HAL_OK)
  {
    Error_Handler();
  }

  /** Configure Analogue filter
  */
  if (HAL_I2CEx_ConfigAnalogFilter(&hi2c4, I2C_ANALOGFILTER_ENABLE) != HAL_OK)
  {
    Error_Handler();
  }

  /** Configure Digital filter
  */
  if (HAL_I2CEx_ConfigDigitalFilter(&hi2c4, 0) != HAL_OK)
  {
    Error_Handler();
  }

}

static void MX_RTC_Init(void)
{

  /** Initialize RTC Only
  */
  hrtc.Instance = RTC;
  hrtc.Init.HourFormat = RTC_HOURFORMAT_24;
  hrtc.Init.AsynchPrediv = 127;
  hrtc.Init.SynchPrediv = 255;
  hrtc.Init.OutPut = RTC_OUTPUT_DISABLE;
  hrtc.Init.OutPutPolarity = RTC_OUTPUT_POLARITY_HIGH;
  hrtc.Init.OutPutType = RTC_OUTPUT_TYPE_OPENDRAIN;
  hrtc.Init.OutPutRemap = RTC_OUTPUT_REMAP_NONE;
  if (HAL_RTC_Init(&hrtc) != HAL_OK)
  {
    Error_Handler();
  }

}

static void MX_SPI1_Init(void)
{

  /* SPI1 parameter configuration*/
  hspi1.Instance = SPI1;
  hspi1.Init.Mode = SPI_MODE_MASTER;
  hspi1.Init.Direction = SPI_DIRECTION_2LINES;
  hspi1.Init.DataSize = SPI_DATASIZE_8BIT;
  hspi1.Init.CLKPolarity = SPI_POLARITY_LOW;
  hspi1.Init.CLKPhase = SPI_PHASE_2EDGE;
  hspi1.Init.NSS = SPI_NSS_SOFT;
  hspi1.Init.BaudRatePrescaler = SPI_BAUDRATEPRESCALER_128;
  hspi1.Init.FirstBit = SPI_FIRSTBIT_MSB;
  hspi1.Init.TIMode = SPI_TIMODE_DISABLE;
  hspi1.Init.CRCCalculation = SPI_CRCCALCULATION_DISABLE;
  hspi1.Init.CRCPolynomial = 0x0;
  hspi1.Init.NSSPMode = SPI_NSS_PULSE_ENABLE;
  hspi1.Init.NSSPolarity = SPI_NSS_POLARITY_LOW;
  hspi1.Init.FifoThreshold = SPI_FIFO_THRESHOLD_01DATA;
  hspi1.Init.TxCRCInitializationPattern = SPI_CRC_INITIALIZATION_ALL_ZERO_PATTERN;
  hspi1.Init.RxCRCInitializationPattern = SPI_CRC_INITIALIZATION_ALL_ZERO_PATTERN;
  hspi1.Init.MasterSSIdleness = SPI_MASTER_SS_IDLENESS_00CYCLE;
  hspi1.Init.MasterInterDataIdleness = SPI_MASTER_INTERDATA_IDLENESS_00CYCLE;
  hspi1.Init.MasterReceiverAutoSusp = SPI_MASTER_RX_AUTOSUSP_DISABLE;
  hspi1.Init.MasterKeepIOState = SPI_MASTER_KEEP_IO_STATE_DISABLE;
  hspi1.Init.IOSwap = SPI_IO_SWAP_DISABLE;
  if (HAL_SPI_Init(&hspi1) != HAL_OK)
  {
    Error_Handler();
  }

}

static void MX_SPI2_Init(void)
{

  /* SPI2 parameter configuration*/
  hspi2.Instance = SPI2;
  hspi2.Init.Mode = SPI_MODE_MASTER;
  hspi2.Init.Direction = SPI_DIRECTION_2LINES;
  hspi2.Init.DataSize = SPI_DATASIZE_8BIT;
  hspi2.Init.CLKPolarity = SPI_POLARITY_LOW;
  hspi2.Init.CLKPhase = SPI_PHASE_1EDGE;
  hspi2.Init.NSS = SPI_NSS_SOFT;
  hspi2.Init.BaudRatePrescaler = SPI_BAUDRATEPRESCALER_64;
  hspi2.Init.FirstBit = SPI_FIRSTBIT_MSB;
  hspi2.Init.TIMode = SPI_TIMODE_DISABLE;
  hspi2.Init.CRCCalculation = SPI_CRCCALCULATION_DISABLE;
  hspi2.Init.CRCPolynomial = 0x0;
  hspi2.Init.NSSPMode = SPI_NSS_PULSE_ENABLE;
  hspi2.Init.NSSPolarity = SPI_NSS_POLARITY_LOW;
  hspi2.Init.FifoThreshold = SPI_FIFO_THRESHOLD_01DATA;
  hspi2.Init.TxCRCInitializationPattern = SPI_CRC_INITIALIZATION_ALL_ZERO_PATTERN;
  hspi2.Init.RxCRCInitializationPattern = SPI_CRC_INITIALIZATION_ALL_ZERO_PATTERN;
  hspi2.Init.MasterSSIdleness = SPI_MASTER_SS_IDLENESS_00CYCLE;
  hspi2.Init.MasterInterDataIdleness = SPI_MASTER_INTERDATA_IDLENESS_00CYCLE;
  hspi2.Init.MasterReceiverAutoSusp = SPI_MASTER_RX_AUTOSUSP_DISABLE;
  hspi2.Init.MasterKeepIOState = SPI_MASTER_KEEP_IO_STATE_DISABLE;
  hspi2.Init.IOSwap = SPI_IO_SWAP_DISABLE;
  if (HAL_SPI_Init(&hspi2) != HAL_OK)
  {
    Error_Handler();
  }

}

static void MX_SPI5_Init(void)
{

  /* SPI5 parameter configuration*/
  hspi5.Instance = SPI5;
  hspi5.Init.Mode = SPI_MODE_MASTER;
  hspi5.Init.Direction = SPI_DIRECTION_2LINES;
  hspi5.Init.DataSize = SPI_DATASIZE_8BIT;
  hspi5.Init.CLKPolarity = SPI_POLARITY_LOW;
  hspi5.Init.CLKPhase = SPI_PHASE_1EDGE;
  hspi5.Init.NSS = SPI_NSS_SOFT;
  hspi5.Init.BaudRatePrescaler = SPI_BAUDRATEPRESCALER_64;
  hspi5.Init.FirstBit = SPI_FIRSTBIT_MSB;
  hspi5.Init.TIMode = SPI_TIMODE_DISABLE;
  hspi5.Init.CRCCalculation = SPI_CRCCALCULATION_DISABLE;
  hspi5.Init.CRCPolynomial = 0x0;
  hspi5.Init.NSSPMode = SPI_NSS_PULSE_ENABLE;
  hspi5.Init.NSSPolarity = SPI_NSS_POLARITY_LOW;
  hspi5.Init.FifoThreshold = SPI_FIFO_THRESHOLD_01DATA;
  hspi5.Init.TxCRCInitializationPattern = SPI_CRC_INITIALIZATION_ALL_ZERO_PATTERN;
  hspi5.Init.RxCRCInitializationPattern = SPI_CRC_INITIALIZATION_ALL_ZERO_PATTERN;
  hspi5.Init.MasterSSIdleness = SPI_MASTER_SS_IDLENESS_00CYCLE;
  hspi5.Init.MasterInterDataIdleness = SPI_MASTER_INTERDATA_IDLENESS_00CYCLE;
  hspi5.Init.MasterReceiverAutoSusp = SPI_MASTER_RX_AUTOSUSP_DISABLE;
  hspi5.Init.MasterKeepIOState = SPI_MASTER_KEEP_IO_STATE_DISABLE;
  hspi5.Init.IOSwap = SPI_IO_SWAP_DISABLE;
  if (HAL_SPI_Init(&hspi5) != HAL_OK)
  {
    Error_Handler();
  }

}

static void MX_TIM2_Init(void)
{

  TIM_ClockConfigTypeDef sClockSourceConfig = {0};
  TIM_MasterConfigTypeDef sMasterConfig = {0};
  TIM_IC_InitTypeDef sConfigIC = {0};

  htim2.Instance = TIM2;
  htim2.Init.Prescaler = 239;
  htim2.Init.CounterMode = TIM_COUNTERMODE_UP;
  htim2.Init.Period = 4294967295;
  htim2.Init.ClockDivision = TIM_CLOCKDIVISION_DIV1;
  htim2.Init.AutoReloadPreload = TIM_AUTORELOAD_PRELOAD_DISABLE;
  if (HAL_TIM_Base_Init(&htim2) != HAL_OK)
  {
    Error_Handler();
  }
  sClockSourceConfig.ClockSource = TIM_CLOCKSOURCE_INTERNAL;
  if (HAL_TIM_ConfigClockSource(&htim2, &sClockSourceConfig) != HAL_OK)
  {
    Error_Handler();
  }
  if (HAL_TIM_IC_Init(&htim2) != HAL_OK)
  {
    Error_Handler();
  }
  sMasterConfig.MasterOutputTrigger = TIM_TRGO_RESET;
  sMasterConfig.MasterSlaveMode = TIM_MASTERSLAVEMODE_DISABLE;
  if (HAL_TIMEx_MasterConfigSynchronization(&htim2, &sMasterConfig) != HAL_OK)
  {
    Error_Handler();
  }
  sConfigIC.ICPolarity = TIM_INPUTCHANNELPOLARITY_RISING;
  sConfigIC.ICSelection = TIM_ICSELECTION_DIRECTTI;
  sConfigIC.ICPrescaler = TIM_ICPSC_DIV1;
  sConfigIC.ICFilter = 0;
  if (HAL_TIM_IC_ConfigChannel(&htim2, &sConfigIC, TIM_CHANNEL_1) != HAL_OK)
  {
    Error_Handler();
  }

}

static void MX_TIM3_Init(void)
{

  TIM_ClockConfigTypeDef sClockSourceConfig = {0};
  TIM_MasterConfigTypeDef sMasterConfig = {0};

  htim3.Instance = TIM3;
  htim3.Init.Prescaler = 0;
  htim3.Init.CounterMode = TIM_COUNTERMODE_UP;
  htim3.Init.Period = 65535;
  htim3.Init.ClockDivision = TIM_CLOCKDIVISION_DIV1;
  htim3.Init.AutoReloadPreload = TIM_AUTORELOAD_PRELOAD_DISABLE;
  if (HAL_TIM_Base_Init(&htim3) != HAL_OK)
  {
    Error_Handler();
  }
  sClockSourceConfig.ClockSource = TIM_CLOCKSOURCE_INTERNAL;
  if (HAL_TIM_ConfigClockSource(&htim3, &sClockSourceConfig) != HAL_OK)
  {
    Error_Handler();
  }
  sMasterConfig.MasterOutputTrigger = TIM_TRGO_RESET;
  sMasterConfig.MasterSlaveMode = TIM_MASTERSLAVEMODE_DISABLE;
  if (HAL_TIMEx_MasterConfigSynchronization(&htim3, &sMasterConfig) != HAL_OK)
  {
    Error_Handler();
  }

}

static void MX_TIM5_Init(void)
{

  TIM_ClockConfigTypeDef sClockSourceConfig = {0};
  TIM_MasterConfigTypeDef sMasterConfig = {0};
  TIM_IC_InitTypeDef sConfigIC = {0};

  htim5.Instance = TIM5;
  htim5.Init.Prescaler = 239;
  htim5.Init.CounterMode = TIM_COUNTERMODE_UP;
  htim5.Init.Period = 4294967295;
  htim5.Init.ClockDivision = TIM_CLOCKDIVISION_DIV1;
  htim5.Init.AutoReloadPreload = TIM_AUTORELOAD_PRELOAD_DISABLE;
  if (HAL_TIM_Base_Init(&htim5) != HAL_OK)
  {
    Error_Handler();
  }
  sClockSourceConfig.ClockSource = TIM_CLOCKSOURCE_INTERNAL;
  if (HAL_TIM_ConfigClockSource(&htim5, &sClockSourceConfig) != HAL_OK)
  {
    Error_Handler();
  }
  if (HAL_TIM_IC_Init(&htim5) != HAL_OK)
  {
    Error_Handler();
  }
  sMasterConfig.MasterOutputTrigger = TIM_TRGO_RESET;
  sMasterConfig.MasterSlaveMode = TIM_MASTERSLAVEMODE_DISABLE;
  if (HAL_TIMEx_MasterConfigSynchronization(&htim5, &sMasterConfig) != HAL_OK)
  {
    Error_Handler();
  }
  sConfigIC.ICPolarity = TIM_INPUTCHANNELPOLARITY_RISING;
  sConfigIC.ICSelection = TIM_ICSELECTION_DIRECTTI;
  sConfigIC.ICPrescaler = TIM_ICPSC_DIV1;
  sConfigIC.ICFilter = 0;
  if (HAL_TIM_IC_ConfigChannel(&htim5, &sConfigIC, TIM_CHANNEL_1) != HAL_OK)
  {
    Error_Handler();
  }

}

static void MX_TIM8_Init(void)
{

  TIM_MasterConfigTypeDef sMasterConfig = {0};
  TIM_OC_InitTypeDef sConfigOC = {0};
  TIM_BreakDeadTimeConfigTypeDef sBreakDeadTimeConfig = {0};

  htim8.Instance = TIM8;
  htim8.Init.Prescaler = 35;
  htim8.Init.CounterMode = TIM_COUNTERMODE_UP;
  htim8.Init.Period = 65535;
  htim8.Init.ClockDivision = TIM_CLOCKDIVISION_DIV1;
  htim8.Init.RepetitionCounter = 0;
  htim8.Init.AutoReloadPreload = TIM_AUTORELOAD_PRELOAD_ENABLE;
  if (HAL_TIM_PWM_Init(&htim8) != HAL_OK)
  {
    Error_Handler();
  }
  sMasterConfig.MasterOutputTrigger = TIM_TRGO_RESET;
  sMasterConfig.MasterOutputTrigger2 = TIM_TRGO2_RESET;
  sMasterConfig.MasterSlaveMode = TIM_MASTERSLAVEMODE_DISABLE;
  if (HAL_TIMEx_MasterConfigSynchronization(&htim8, &sMasterConfig) != HAL_OK)
  {
    Error_Handler();
  }
  sConfigOC.OCMode = TIM_OCMODE_PWM1;
  sConfigOC.Pulse = 0;
  sConfigOC.OCPolarity = TIM_OCPOLARITY_HIGH;
  sConfigOC.OCNPolarity = TIM_OCNPOLARITY_HIGH;
  sConfigOC.OCFastMode = TIM_OCFAST_DISABLE;
  sConfigOC.OCIdleState = TIM_OCIDLESTATE_RESET;
  sConfigOC.OCNIdleState = TIM_OCNIDLESTATE_RESET;
  if (HAL_TIM_PWM_ConfigChannel(&htim8, &sConfigOC, TIM_CHANNEL_2) != HAL_OK)
  {
    Error_Handler();
  }
  sBreakDeadTimeConfig.OffStateRunMode = TIM_OSSR_DISABLE;
  sBreakDeadTimeConfig.OffStateIDLEMode = TIM_OSSI_DISABLE;
  sBreakDeadTimeConfig.LockLevel = TIM_LOCKLEVEL_OFF;
  sBreakDeadTimeConfig.DeadTime = 0;
  sBreakDeadTimeConfig.BreakState = TIM_BREAK_DISABLE;
  sBreakDeadTimeConfig.BreakPolarity = TIM_BREAKPOLARITY_HIGH;
  sBreakDeadTimeConfig.BreakFilter = 0;
  sBreakDeadTimeConfig.Break2State = TIM_BREAK2_DISABLE;
  sBreakDeadTimeConfig.Break2Polarity = TIM_BREAK2POLARITY_HIGH;
  sBreakDeadTimeConfig.Break2Filter = 0;
  sBreakDeadTimeConfig.AutomaticOutput = TIM_AUTOMATICOUTPUT_DISABLE;
  if (HAL_TIMEx_ConfigBreakDeadTime(&htim8, &sBreakDeadTimeConfig) != HAL_OK)
  {
    Error_Handler();
  }
  HAL_TIM_MspPostInit(&htim8);

}

static void MX_UART8_Init(void)
{

  huart8.Instance = UART8;
  huart8.Init.BaudRate = 115200;
  huart8.Init.WordLength = UART_WORDLENGTH_8B;
  huart8.Init.StopBits = UART_STOPBITS_1;
  huart8.Init.Parity = UART_PARITY_NONE;
  huart8.Init.Mode = UART_MODE_TX_RX;
  huart8.Init.HwFlowCtl = UART_HWCONTROL_NONE;
  huart8.Init.OverSampling = UART_OVERSAMPLING_16;
  huart8.Init.OneBitSampling = UART_ONE_BIT_SAMPLE_DISABLE;
  huart8.Init.ClockPrescaler = UART_PRESCALER_DIV1;
  huart8.AdvancedInit.AdvFeatureInit = UART_ADVFEATURE_NO_INIT;
  if (HAL_UART_Init(&huart8) != HAL_OK)
  {
    Error_Handler();
  }
  if (HAL_UARTEx_SetTxFifoThreshold(&huart8, UART_TXFIFO_THRESHOLD_1_8) != HAL_OK)
  {
    Error_Handler();
  }
  if (HAL_UARTEx_SetRxFifoThreshold(&huart8, UART_RXFIFO_THRESHOLD_1_8) != HAL_OK)
  {
    Error_Handler();
  }
  if (HAL_UARTEx_DisableFifoMode(&huart8) != HAL_OK)
  {
    Error_Handler();
  }

}

static void MX_USART3_UART_Init(void)
{

  huart3.Instance = USART3;
  huart3.Init.BaudRate = 460800;
  huart3.Init.WordLength = UART_WORDLENGTH_8B;
  huart3.Init.StopBits = UART_STOPBITS_1;
  huart3.Init.Parity = UART_PARITY_NONE;
  huart3.Init.Mode = UART_MODE_TX_RX;
  huart3.Init.HwFlowCtl = UART_HWCONTROL_NONE;
  huart3.Init.OverSampling = UART_OVERSAMPLING_16;
  huart3.Init.OneBitSampling = UART_ONE_BIT_SAMPLE_DISABLE;
  huart3.Init.ClockPrescaler = UART_PRESCALER_DIV1;
  huart3.AdvancedInit.AdvFeatureInit = UART_ADVFEATURE_NO_INIT;
  if (HAL_UART_Init(&huart3) != HAL_OK)
  {
    Error_Handler();
  }
  if (HAL_UARTEx_SetTxFifoThreshold(&huart3, UART_TXFIFO_THRESHOLD_1_8) != HAL_OK)
  {
    Error_Handler();
  }
  if (HAL_UARTEx_SetRxFifoThreshold(&huart3, UART_RXFIFO_THRESHOLD_1_8) != HAL_OK)
  {
    Error_Handler();
  }
  if (HAL_UARTEx_DisableFifoMode(&huart3) != HAL_OK)
  {
    Error_Handler();
  }

}

static void MX_DMA_Init(void)
{

  /* DMA controller clock enable */
  __HAL_RCC_DMA1_CLK_ENABLE();
  __HAL_RCC_DMA2_CLK_ENABLE();

  /* DMA interrupt init */
  /* DMA1_Stream0_IRQn interrupt configuration */
  HAL_NVIC_SetPriority(DMA1_Stream0_IRQn, 5, 0);
  HAL_NVIC_EnableIRQ(DMA1_Stream0_IRQn);
  /* DMA1_Stream1_IRQn interrupt configuration */
  HAL_NVIC_SetPriority(DMA1_Stream1_IRQn, 5, 0);
  HAL_NVIC_EnableIRQ(DMA1_Stream1_IRQn);
  /* DMA2_Stream1_IRQn interrupt configuration */
  HAL_NVIC_SetPriority(DMA2_Stream1_IRQn, 5, 0);
  HAL_NVIC_EnableIRQ(DMA2_Stream1_IRQn);

}

static void MX_GPIO_Init(void)
{
  GPIO_InitTypeDef GPIO_InitStruct = {0};

  /* GPIO Ports Clock Enable */
  __HAL_RCC_GPIOI_CLK_ENABLE();
  __HAL_RCC_GPIOB_CLK_ENABLE();
  __HAL_RCC_GPIOG_CLK_ENABLE();
  __HAL_RCC_GPIOD_CLK_ENABLE();
  __HAL_RCC_GPIOA_CLK_ENABLE();
  __HAL_RCC_GPIOE_CLK_ENABLE();
  __HAL_RCC_GPIOJ_CLK_ENABLE();
  __HAL_RCC_GPIOH_CLK_ENABLE();
  __HAL_RCC_GPIOC_CLK_ENABLE();
  __HAL_RCC_GPIOF_CLK_ENABLE();
  __HAL_RCC_GPIOK_CLK_ENABLE();

  /*Configure GPIO pin Output Level */
  HAL_GPIO_WritePin(GPIOI, GPIO_PIN_5|GPIO_PIN_4|GPIO_PIN_1|GPIO_PIN_7
                          |GPIO_PIN_3|GPIO_PIN_8|GPIO_PIN_10|GPIO_PIN_11
                          |GPIO_PIN_15, GPIO_PIN_RESET);

  /*Configure GPIO pin Output Level */
  HAL_GPIO_WritePin(GPIOG, GPIO_PIN_10|GPIO_PIN_12|GPIO_PIN_7|GPIO_PIN_5
                          |GPIO_PIN_6|GPIO_PIN_4, GPIO_PIN_RESET);

  /*Configure GPIO pin Output Level */
  HAL_GPIO_WritePin(GPIOD, GPIO_PIN_5|GPIO_PIN_4|GPIO_PIN_3|GPIO_PIN_1
                          |GPIO_PIN_14|GPIO_PIN_11, GPIO_PIN_RESET);

  /*Configure GPIO pin Output Level */
  HAL_GPIO_WritePin(GPIOJ, GPIO_PIN_15|GPIO_PIN_12|GPIO_PIN_8|GPIO_PIN_1, GPIO_PIN_RESET);

  /*Configure GPIO pin Output Level */
  HAL_GPIO_WritePin(GPIOH, GPIO_PIN_14|GPIO_PIN_10|GPIO_PIN_11|GPIO_PIN_8
                          |GPIO_PIN_7, GPIO_PIN_RESET);

  /*Configure GPIO pin Output Level */
  HAL_GPIO_WritePin(GPIOE, GPIO_PIN_2|GPIO_PIN_6|GPIO_PIN_10|GPIO_PIN_11, GPIO_PIN_RESET);

  /*Configure GPIO pin Output Level */
  HAL_GPIO_WritePin(GPIOB, GPIO_PIN_9|GPIO_PIN_10|GPIO_PIN_11|GPIO_PIN_12, GPIO_PIN_RESET);

  /*Configure GPIO pin Output Level */
  HAL_GPIO_WritePin(GPIOC, GPIO_PIN_13|GPIO_PIN_1, GPIO_PIN_RESET);

  /*Configure GPIO pin Output Level */
  HAL_GPIO_WritePin(GPIOJ, GPIO_PIN_13|GPIO_PIN_3, GPIO_PIN_SET);

  /*Configure GPIO pin Output Level */
  HAL_GPIO_WritePin(GPIOK, GPIO_PIN_1, GPIO_PIN_RESET);

  /*Configure GPIO pin Output Level */
  HAL_GPIO_WritePin(GPIOF, GPIO_PIN_13, GPIO_PIN_SET);

  /*Configure GPIO pins : PI5 PI4 PI1 PI7
                           PI3 PI8 PI10 PI11
                           PI15 */
  GPIO_InitStruct.Pin = GPIO_PIN_5|GPIO_PIN_4|GPIO_PIN_1|GPIO_PIN_7
                          |GPIO_PIN_3|GPIO_PIN_8|GPIO_PIN_10|GPIO_PIN_11
                          |GPIO_PIN_15;
  GPIO_InitStruct.Mode = GPIO_MODE_OUTPUT_PP;
  GPIO_InitStruct.Pull = GPIO_NOPULL;
  GPIO_InitStruct.Speed = GPIO_SPEED_FREQ_LOW;
  HAL_GPIO_Init(GPIOI, &GPIO_InitStruct);

  /*Configure GPIO pins : PG10 PG12 PG7 PG5
                           PG6 PG4 */
  GPIO_InitStruct.Pin = GPIO_PIN_10|GPIO_PIN_12|GPIO_PIN_7|GPIO_PIN_5
                          |GPIO_PIN_6|GPIO_PIN_4;
  GPIO_InitStruct.Mode = GPIO_MODE_OUTPUT_PP;
  GPIO_InitStruct.Pull = GPIO_NOPULL;
  GPIO_InitStruct.Speed = GPIO_SPEED_FREQ_LOW;
  HAL_GPIO_Init(GPIOG, &GPIO_InitStruct);

  /*Configure GPIO pins : PD5 PD4 PD3 PD1
                           PD14 PD11 */
  GPIO_InitStruct.Pin = GPIO_PIN_5|GPIO_PIN_4|GPIO_PIN_3|GPIO_PIN_1
                          |GPIO_PIN_14|GPIO_PIN_11;
  GPIO_InitStruct.Mode = GPIO_MODE_OUTPUT_PP;
  GPIO_InitStruct.Pull = GPIO_NOPULL;
  GPIO_InitStruct.Speed = GPIO_SPEED_FREQ_LOW;
  HAL_GPIO_Init(GPIOD, &GPIO_InitStruct);

  /*Configure GPIO pins : PJ15 PJ12 PJ13 PJ8
                           PJ1 PJ3 */
  GPIO_InitStruct.Pin = GPIO_PIN_15|GPIO_PIN_12|GPIO_PIN_13|GPIO_PIN_8
                          |GPIO_PIN_1|GPIO_PIN_3;
  GPIO_InitStruct.Mode = GPIO_MODE_OUTPUT_PP;
  GPIO_InitStruct.Pull = GPIO_NOPULL;
  GPIO_InitStruct.Speed = GPIO_SPEED_FREQ_LOW;
  HAL_GPIO_Init(GPIOJ, &GPIO_InitStruct);

  /*Configure GPIO pin : PI2 */
  GPIO_InitStruct.Pin = GPIO_PIN_2;
  GPIO_InitStruct.Mode = GPIO_MODE_INPUT;
  GPIO_InitStruct.Pull = GPIO_NOPULL;
  HAL_GPIO_Init(GPIOI, &GPIO_InitStruct);

  /*Configure GPIO pin : PH15 */
  GPIO_InitStruct.Pin = GPIO_PIN_15;
  GPIO_InitStruct.Mode = GPIO_MODE_INPUT;
  GPIO_InitStruct.Pull = GPIO_NOPULL;
  HAL_GPIO_Init(GPIOH, &GPIO_InitStruct);

  /*Configure GPIO pins : PH14 PH10 PH11 PH8
                           PH7 */
  GPIO_InitStruct.Pin = GPIO_PIN_14|GPIO_PIN_10|GPIO_PIN_11|GPIO_PIN_8
                          |GPIO_PIN_7;
  GPIO_InitStruct.Mode = GPIO_MODE_OUTPUT_PP;
  GPIO_InitStruct.Pull = GPIO_NOPULL;
  GPIO_InitStruct.Speed = GPIO_SPEED_FREQ_LOW;
  HAL_GPIO_Init(GPIOH, &GPIO_InitStruct);

  /*Configure GPIO pins : PE2 PE6 PE10 PE11 */
  GPIO_InitStruct.Pin = GPIO_PIN_2|GPIO_PIN_6|GPIO_PIN_10|GPIO_PIN_11;
  GPIO_InitStruct.Mode = GPIO_MODE_OUTPUT_PP;
  GPIO_InitStruct.Pull = GPIO_NOPULL;
  GPIO_InitStruct.Speed = GPIO_SPEED_FREQ_LOW;
  HAL_GPIO_Init(GPIOE, &GPIO_InitStruct);

  /*Configure GPIO pins : PB9 PB10 PB11 PB12 */
  GPIO_InitStruct.Pin = GPIO_PIN_9|GPIO_PIN_10|GPIO_PIN_11|GPIO_PIN_12;
  GPIO_InitStruct.Mode = GPIO_MODE_OUTPUT_PP;
  GPIO_InitStruct.Pull = GPIO_NOPULL;
  GPIO_InitStruct.Speed = GPIO_SPEED_FREQ_LOW;
  HAL_GPIO_Init(GPIOB, &GPIO_InitStruct);

  /*Configure GPIO pin : PB8 */
  GPIO_InitStruct.Pin = GPIO_PIN_8;
  GPIO_InitStruct.Mode = GPIO_MODE_ANALOG;
  GPIO_InitStruct.Pull = GPIO_NOPULL;
  HAL_GPIO_Init(GPIOB, &GPIO_InitStruct);

  /*Configure GPIO pins : PC13 PC1 */
  GPIO_InitStruct.Pin = GPIO_PIN_13|GPIO_PIN_1;
  GPIO_InitStruct.Mode = GPIO_MODE_OUTPUT_PP;
  GPIO_InitStruct.Pull = GPIO_NOPULL;
  GPIO_InitStruct.Speed = GPIO_SPEED_FREQ_LOW;
  HAL_GPIO_Init(GPIOC, &GPIO_InitStruct);

  /*Configure GPIO pin : PK2 */
  GPIO_InitStruct.Pin = GPIO_PIN_2;
  GPIO_InitStruct.Mode = GPIO_MODE_INPUT;
  GPIO_InitStruct.Pull = GPIO_NOPULL;
  HAL_GPIO_Init(GPIOK, &GPIO_InitStruct);

  /*Configure GPIO pin : PK1 */
  GPIO_InitStruct.Pin = GPIO_PIN_1;
  GPIO_InitStruct.Mode = GPIO_MODE_OUTPUT_PP;
  GPIO_InitStruct.Pull = GPIO_NOPULL;
  GPIO_InitStruct.Speed = GPIO_SPEED_FREQ_LOW;
  HAL_GPIO_Init(GPIOK, &GPIO_InitStruct);

  /*Configure GPIO pin : PF13 */
  GPIO_InitStruct.Pin = GPIO_PIN_13;
  GPIO_InitStruct.Mode = GPIO_MODE_OUTPUT_PP;
  GPIO_InitStruct.Pull = GPIO_NOPULL;
  GPIO_InitStruct.Speed = GPIO_SPEED_FREQ_LOW;
  HAL_GPIO_Init(GPIOF, &GPIO_InitStruct);

  /*Configure GPIO pin : PF14 */
  GPIO_InitStruct.Pin = GPIO_PIN_14;
  GPIO_InitStruct.Mode = GPIO_MODE_INPUT;
  GPIO_InitStruct.Pull = GPIO_PULLUP;
  HAL_GPIO_Init(GPIOF, &GPIO_InitStruct);

}

void StartTestTask(void *argument)
{
  /* USER CODE BEGIN 5 */
  task_test_init();
  /* Infinite loop */
  for(;;)
  {
	task_test_loop();
  }
  /* USER CODE END 5 */
}

void StartSlowTask(void *argument)
{
  /* USER CODE BEGIN StartSlowTask */
  task_slow_init();
  /* Infinite loop */
  for(;;)
  {
    task_slow_loop();
  }
  /* USER CODE END StartSlowTask */
}

void StartMediumTask(void *argument)
{
  /* USER CODE BEGIN StartMediumTask */
  task_medium_init();
  /* Infinite loop */
  for(;;)
  {
    task_medium_loop();
  }
  /* USER CODE END StartMediumTask */
}

void StartFastTask(void *argument)
{
  /* USER CODE BEGIN StartFastTask */
  task_fast_init();
  /* Infinite loop */
  for(;;)
  {
    task_fast_loop();
  }
  /* USER CODE END StartFastTask */
}

void StartCanClassicTx(void *argument)
{
  /* USER CODE BEGIN StartCanClassicTx */
  task_can_classic_tx_init();
  /* Infinite loop */
  for(;;)
  {
    task_can_classic_tx_loop();
  }
  /* USER CODE END StartCanClassicTx */
}

void StartCanClassicRx(void *argument)
{
  /* USER CODE BEGIN StartCanClassicRx */
  task_can_classic_rx_init();
  /* Infinite loop */
  for(;;)
  {
    task_can_classic_rx_loop();
  }
  /* USER CODE END StartCanClassicRx */
}

void StartManagerTask(void *argument)
{
  /* USER CODE BEGIN StartManagerTask */
  task_manager_init();
  /* Infinite loop */
  for(;;)
  {
	  task_manager_loop();
  }
  /* USER CODE END StartManagerTask */
}

void StartVeryFastTask(void *argument)
{
  /* USER CODE BEGIN StartVeryFastTask */
  task_very_fast_init();
  /* Infinite loop */
  for(;;)
  {
    task_very_fast_loop();
  }
  /* USER CODE END StartVeryFastTask */
}

 /* MPU Configuration */

void MPU_Config(void)
{
  MPU_Region_InitTypeDef MPU_InitStruct = {0};

  /* Disables the MPU */
  HAL_MPU_Disable();

  /** Initializes and configures the Region and the memory to be protected
  */
  MPU_InitStruct.Enable = MPU_REGION_ENABLE;
  MPU_InitStruct.Number = MPU_REGION_NUMBER0;
  MPU_InitStruct.BaseAddress = 0x0;
  MPU_InitStruct.Size = MPU_REGION_SIZE_4GB;
  MPU_InitStruct.SubRegionDisable = 0x87;
  MPU_InitStruct.TypeExtField = MPU_TEX_LEVEL0;
  MPU_InitStruct.AccessPermission = MPU_REGION_NO_ACCESS;
  MPU_InitStruct.DisableExec = MPU_INSTRUCTION_ACCESS_DISABLE;
  MPU_InitStruct.IsShareable = MPU_ACCESS_SHAREABLE;
  MPU_InitStruct.IsCacheable = MPU_ACCESS_NOT_CACHEABLE;
  MPU_InitStruct.IsBufferable = MPU_ACCESS_NOT_BUFFERABLE;

  HAL_MPU_ConfigRegion(&MPU_InitStruct);
  /* Enables the MPU */
  HAL_MPU_Enable(MPU_PRIVILEGED_DEFAULT);

}

void HAL_TIM_PeriodElapsedCallback(TIM_HandleTypeDef *htim)
{
  if (htim->Instance == TIM1)
  {
    HAL_IncTick();
  }
}

void Error_Handler(void)
{
  __disable_irq();
  while (1)
  {
  }
}
